# GD32W515Px register map
File version: 1.0
CPU: CM33 r0p0, little endian, MPU, FPU, 4 interrupt priority bits
Registers are 32-bit, read-write, reset 0x0 unless marked. A register's access mark holds for its fields unless they carry their own. Offsets are from the block's base; [hi:lo] are bit positions; {n}, {i} and the like mark numbered series; 'fields as' and 'values as' point back to an identical list.

## SQPI — Serial/Quad Parallel Interface
Base 0x40025400
Same registers: SEC_SQPI 0x50025400
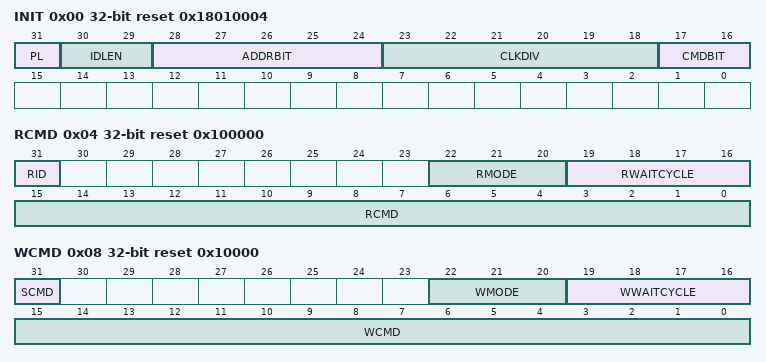
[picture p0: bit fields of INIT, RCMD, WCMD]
0x00 INIT reset 0x18010004 — SQPI Initial Register
  [31] PL — Read data sample polarity.
  [30:29] IDLEN — SQPI controller external memory ID length
  [28:24] ADDRBIT — Bit number of SPI PSRAM address phase.
  [23:18] CLKDIV — Clock divider for SQPI output clock
  [17:16] CMDBIT — Bit number of SQPI controller command phase
0x04 RCMD reset 0x100000 — SQPI Read Command Register
  [31] RID — Send read ID command
  [22:20] RMODE — SQPI controller read command mode
  [19:16] RWAITCYCLE — SQPI read command waitcycle number after address phase
  [15:0] RCMD — SQPI read command for AHB read transfer
0x08 WCMD reset 0x10000 — Write Command Register
  [31] SCMD — Send special command
  [22:20] WMODE — SQPI controller write command mode
  [19:16] WWAITCYCLE — SQPI write command waitcycle number after address phase
  [15:0] WCMD — SQPI write command for AHB write transfer
0x0C IDL ro — ID Low Register
  [31:0] IDL — ID Low Data saved for SQPI Read ID Command
0x10 IDH ro — ID High Register
  [31:0] IDH — ID High Data saved for SQPI read ID command

## USART1 — Universal synchronous asynchronous receiver transmitter
Base 0x40004400
Same registers: SEC_USART1 0x50004400
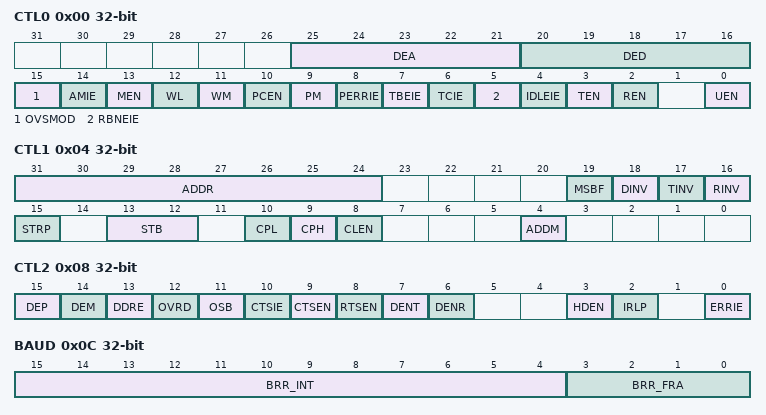
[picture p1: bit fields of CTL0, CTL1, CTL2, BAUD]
0x00 CTL0 — Control register 0
  [25:21] DEA — Driver Enable assertion time
  [20:16] DED — Driver Enable deassertion time
  [15] OVSMOD — Oversampling mode
  [14] AMIE — Character match interrupt enable
  [13] MEN — Mute mode enable
  [12] WL — Word length
  [11] WM — Receiver wakeup method
  [10] PCEN — Parity control enable
  [9] PM — Parity selection
  [8] PERRIE — PE interrupt enable
  [7] TBEIE — interrupt enable
  [6] TCIE — Transmission complete interrupt enable
  [5] RBNEIE — RXNE interrupt enable
  [4] IDLEIE — IDLE interrupt enable
  [3] TEN — Transmitter enable
  [2] REN — Receiver enable
  [0] UEN — USART enable
0x04 CTL1 — Control register 1
  [31:24] ADDR — Address of the USART terminal
  [19] MSBF — Most significant bit first
  [18] DINV — Data bit level inversion
  [17] TINV — TX pin active level inversion
  [16] RINV — RX pin active level inversion
  [15] STRP — Swap TX/RX pins
  [13:12] STB — STOP bits
  [10] CPL — Clock polarity
  [9] CPH — Clock phase
  [8] CLEN — Last bit clock pulse
  [4] ADDM — 7-bit Address Detection/4-bit Address Detection
0x08 CTL2 — Control register 2
  [15] DEP — Driver enable polarity selection
  [14] DEM — Driver enable mode
  [13] DDRE — DMA Disable on Reception Error
  [12] OVRD — Overrun Disable
  [11] OSB — One sample bit method enable
  [10] CTSIE — CTS interrupt enable
  [9] CTSEN — CTS enable
  [8] RTSEN — RTS enable
  [7] DENT — DMA enable transmitter
  [6] DENR — DMA enable receiver
  [3] HDEN — Half-duplex selection
  [2] IRLP — IrDA low-power
  [0] ERRIE — Error interrupt enable
0x0C BAUD — Baud rate register
  [15:4] BRR_INT — integer of baud-rate divider
  [3:0] BRR_FRA — integer of baud-rate divider
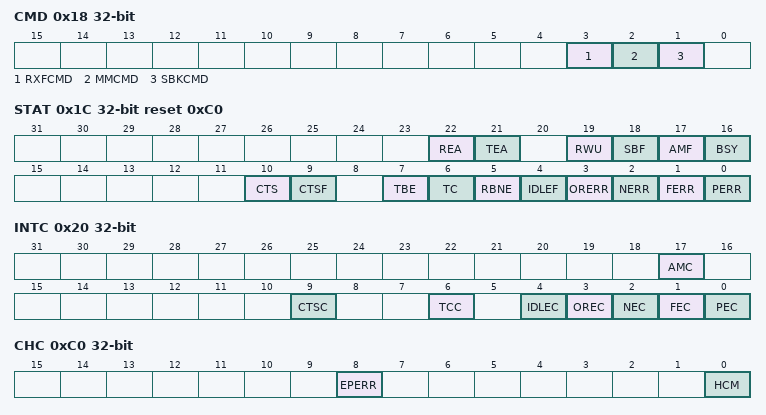
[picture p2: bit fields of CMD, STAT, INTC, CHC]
0x18 CMD wo — Command register
  [3] RXFCMD — Receive data flush request
  [2] MMCMD — Mute mode request
  [1] SBKCMD — Send break request
0x1C STAT ro reset 0xC0 — Interrupt & status register
  [22] REA — Receive enable acknowledge flag
  [21] TEA — Transmit enable acknowledge flag
  [19] RWU — Receiver wakeup from Mute mode
  [18] SBF — Send break flag
  [17] AMF — character match flag
  [16] BSY — Busy flag
  [10] CTS — CTS flag
  [9] CTSF — CTS interrupt flag
  [7] TBE — Transmit data register empty
  [6] TC — Transmission complete
  [5] RBNE — Read data register not empty
  [4] IDLEF — Idle line detected
  [3] ORERR — Overrun error
  [2] NERR — Noise detected flag
  [1] FERR — Framing error
  [0] PERR — Parity error
0x20 INTC wo — Interrupt flag clear register
  [17] AMC — Character match clear flag
  [9] CTSC — CTS clear flag
  [6] TCC — Transmission complete clear flag
  [4] IDLEC — Idle line detected clear flag
  [3] OREC — Overrun error clear flag
  [2] NEC — Noise detected clear flag
  [1] FEC — Frame error clear flag
  [0] PEC — Parity error clear flag
0x24 RDATA ro — Receive data register
  [8:0] RDATA — Receive data value
0x28 TDATA — Transmit data register
  [8:0] TDATA — Transmit data value
0xC0 CHC — coherence control register
  [8] EPERR — Early parity error flag
  [0] HCM — Hardware flow control coherence mode
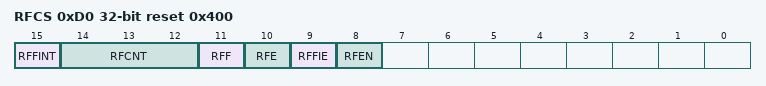
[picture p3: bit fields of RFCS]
0xD0 RFCS access per field reset 0x400 — USART receive FIFO control and status register
  [15] RFFINT rw — Receive FIFO full interrupt flag
  [14:12] RFCNT ro — Receive FIFO count number
  [11] RFF ro — Receive FIFO full flag
  [10] RFE ro — Receive FIFO empty flag
  [9] RFFIE rw — Receive FIFO full interrupt enable
  [8] RFEN rw — Receive FIFO enable

## FS_HOST — USB on the go full speed host
Base 0x49000400
Same registers: SEC_FS_HOST 0x59000400
0x00 HCTL — host configuration register (HCTL)
  [1:0] CLKSEL — clock select for USB clock
0x04 HFT reset 0xBB80 — Host frame interval register
  [15:0] FRI — Frame interval
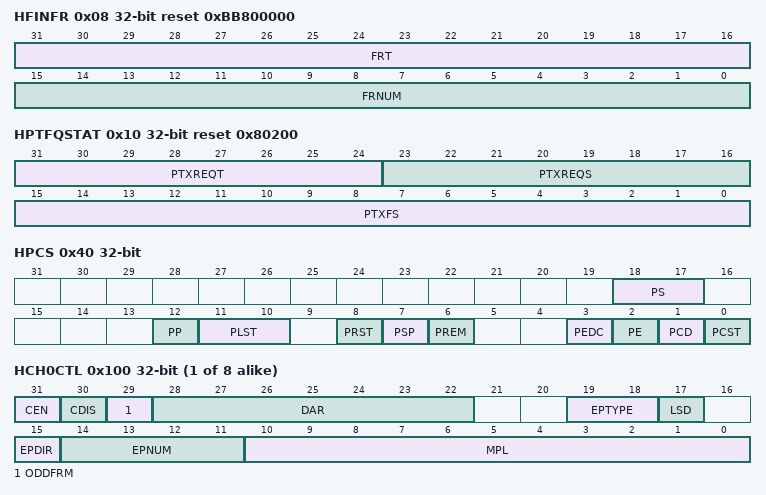
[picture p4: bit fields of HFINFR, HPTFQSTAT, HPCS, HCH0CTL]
0x08 HFINFR ro reset 0xBB800000 — OTG_FS host frame number/frame time remaining register (HFINFR)
  [31:16] FRT — Frame remaining time
  [15:0] FRNUM — Frame number
0x10 HPTFQSTAT ro reset 0x80200 — Host periodic transmit FIFO/queue status register (HPTFQSTAT)
  [31:24] PTXREQT — Top of the periodic transmit request queue
  [23:16] PTXREQS — Periodic transmit request queue space available
  [15:0] PTXFS — Periodic transmit data FIFO space available
0x14 HACHINT ro — Host all channels interrupt register
  [7:0] HACHINT — Host all channel interrupts
0x18 HACHINTEN — host all channels interrupt mask register
  [7:0] CINTEN — Channel interrupt enable
0x40 HPCS access per field — Host port control and status register (USBFS_HPCS)
  [18:17] PS ro — Port speed
  [12] PP rw — Port power
  [11:10] PLST ro — Port line status
  [8] PRST rw — Port reset
  [7] PSP rw — Port suspend
  [6] PREM rw — Port resume
  [3] PEDC rw — Port enable/disable change
  [2] PE rw — Port enable
  [1] PCD rw — Port connect detected
  [0] PCST ro — Port connect status
{0x100+0x20*i} HCH{i}CTL (i=0..7) — host channel-{i} characteristics register (HCH{i}CTL)
  [31] CEN — Channel enable
  [30] CDIS — Channel disable
  [29] ODDFRM — Odd frame
  [28:22] DAR — Device address
  [19:18] EPTYPE — Endpoint type
  [17] LSD — Low-speed device
  [15] EPDIR — Endpoint direction
  [14:11] EPNUM — Endpoint number
  [10:0] MPL — Maximum packet size
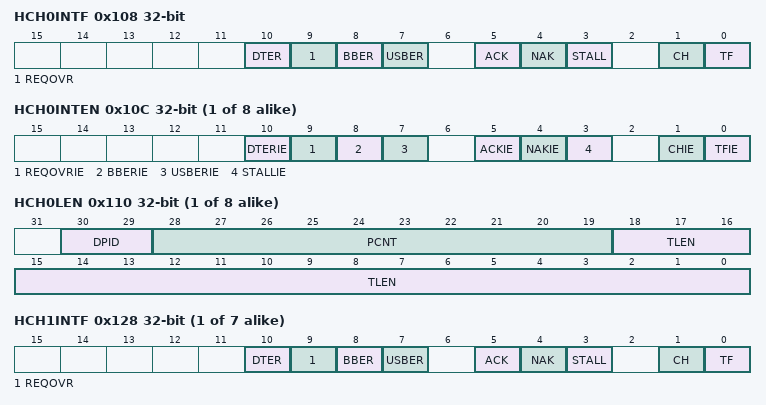
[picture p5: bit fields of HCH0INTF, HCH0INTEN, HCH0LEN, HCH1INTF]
0x108 HCH0INTF — host channel-0 interrupt register (USBFS_HCHxINTF)
  [10] DTER — Data toggle error
  [9] REQOVR — Request queue overrun
  [8] BBER — Babble error
  [7] USBER — USB bus error
  [5] ACK — ACK response received/transmitted interrupt
  [4] NAK — NAK response received interrupt
  [3] STALL — STALL response received interrupt
  [1] CH — Channel halted
  [0] TF — Transfer finished
{0x10C+0x20*i} HCH{i}INTEN (i=0..7) — host channel-{i} interrupt enable register (HCH{i}INTEN)
  [10] DTERIE — Data toggle error interrupt enable
  [9] REQOVRIE — request queue overrun interrupt enable
  [8] BBERIE — Babble error interrupt enable
  [7] USBERIE — USB bus error interrupt enable
  [5] ACKIE — ACK interrupt enable
  [4] NAKIE — NAK interrupt enable
  [3] STALLIE — STALL interrupt enable
  [1] CHIE — Channel halted interrupt enable
  [0] TFIE — Transfer completed interrupt enable
{0x110+0x20*i} HCH{i}LEN (i=0..7) — host channel-{i} transfer length register
  [30:29] DPID — Data PID
  [28:19] PCNT — Packet count
  [18:0] TLEN — Transfer length
{0x108+0x20*i} HCH{i}INTF (i=1..7) — host channel-{i} interrupt register (HCH{i}INTF)
  fields as HCH0INTF

## FS_PWRCLK — USB on the go full speed
Base 0x49000E00
Same registers: SEC_FS_PWRCLK 0x59000E00
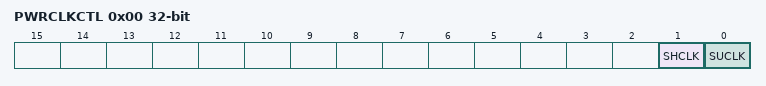
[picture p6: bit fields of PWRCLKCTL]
0x00 PWRCLKCTL — power and clock gating control register (PWRCLKCTL)
  [1] SHCLK — Stop HCLK
  [0] SUCLK — Stop the USB clock
